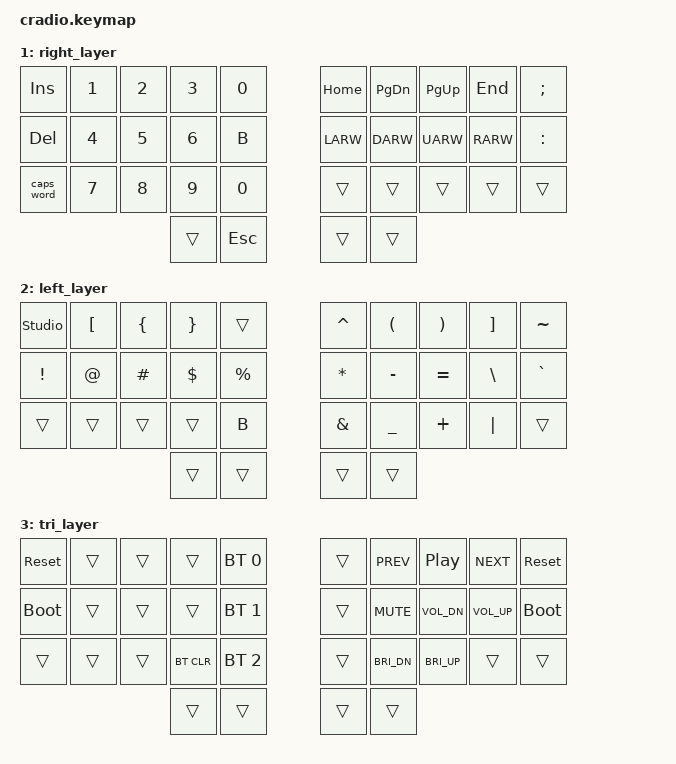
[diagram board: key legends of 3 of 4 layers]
// Copyright (c) 2022 The ZMK Contributors
// SPDX-License-Identifier: MIT

#include <behaviors.dtsi>
#include <dt-bindings/zmk/keys.h>
#include <dt-bindings/zmk/bt.h>

// Home row mods macro
#define HRML(k1,k2,k3,k4) &ht LCTRL k1  &ht LGUI k2  &ht LSHFT k3  &ht LALT k4
#define HRMR(k1,k2,k3,k4) &ht RALT k1  &ht RSHFT k2  &ht RGUI k3  &ht RCTRL k4

/ {
    behaviors {
        ht: hold_tap {
            compatible = "zmk,behavior-hold-tap";
            #binding-cells = <2>;
            flavor = "tap-preferred";
            tapping-term-ms = <220>;
            quick-tap-ms = <150>;
            require-prior-idle-ms = <100>;
            bindings = <&kp>, <&kp>;
        };
    };

    conditional_layers {
        compatible = "zmk,conditional-layers";
        tri_layer {
            if-layers = <1 2>;
            then-layer = <3>;
        };
    };

    keymap {
        compatible = "zmk,keymap";
        default_layer {
            bindings = <
        //╭──────────┬──────────┬──────────┬──────────┬──────────╮   ╭──────────┬──────────┬──────────┬──────────┬──────────╮
        //│  Q       │  W       │  E       │  R       │  T       │   │  Y       │  U       │  I       │  O       │  P       │
            &kp Q      &kp W      &kp E      &kp R      &kp T          &kp Y      &kp U      &kp I      &kp O      &kp P
        //├──────────┼──────────┼──────────┼──────────┼──────────┤   ├──────────┼──────────┼──────────┼──────────┼──────────┤
        //│  A       │  S       │  D       │  F       │  G       │   │  H       │  J       │  K       │  L       │ ' "      │
            HRML(A,        S,         D,         F)     &kp G          &kp H      HRMR(J,        K,         L,        SQT)
        //├──────────┼──────────┼──────────┼──────────┼──────────┤   ├──────────┼──────────┼──────────┼──────────┼──────────┤
        //│  Z       │  X       │  C       │  V       │  B       │   │  N       │  M       │ , <      │ . >      │ / ?      │
            &kp Z      &kp X      &kp C      &kp V      &kp B          &kp N      &kp M      &kp COMMA  &kp DOT    &kp FSLH
        //╰──────────┴──────────┴──────────┼──────────┼──────────┤   ├──────────┼──────────┼──────────┴──────────┴──────────╯
                                            &lt 2 TAB   &kp SPACE    &kp ENTER  &lt 1 BSPC
        //                                 ╰──────────┴──────────╯   ╰──────────┴──────────╯
            >;
        };

	// Кнопка B сломалась(((
        right_layer {
            bindings = <
        //╭──────────┬──────────┬──────────┬──────────┬──────────╮   ╭──────────┬──────────┬──────────┬──────────┬──────────╮
        //│ INSERT   │  1       │  2       │  3       │  0       │   │ HOME     │ PAGE DN  │ PAGE UP  │ END      │  ;       │
            &kp INS    &kp N1     &kp N2     &kp N3     &kp N0         &kp HOME   &kp PG_DN  &kp PG_UP  &kp END    &kp SEMI
        //├──────────┼──────────┼──────────┼──────────┼──────────┤   ├──────────┼──────────┼──────────┼──────────┼──────────┤
        //│ DELETE   │  4       │  5       │  6       │  B       │   │ LEFT     │ DOWN     │ UP       │ RIGHT    │  :       │
            &kp DEL    &kp N4     &kp N5     &kp N6     &kp B          &kp LARW   &kp DARW   &kp UARW   &kp RARW   &kp COLON
        //├──────────┼──────────┼──────────┼──────────┼──────────┤   ├──────────┼──────────┼──────────┼──────────┼──────────┤
        //│ CAPS     │  7       │  8       │  9       │  0       │   │          │          │          │          │          │
           &caps_word  &kp N7     &kp N8     &kp N9     &kp N0         &trans     &trans     &trans     &trans     &trans
        //╰──────────┴──────────┴──────────┼──────────┼──────────┤   ├──────────┼──────────┼──────────┴──────────┴──────────╯
                                             &trans     &kp ESC        &trans     &trans
        //                                 ╰──────────┴──────────╯   ╰──────────┴──────────╯
            >;
        };

        left_layer {
            bindings = <
        //╭──────────┬──────────┬──────────┬──────────┬──────────╮   ╭──────────┬──────────┬──────────┬──────────┬──────────╮
        //│          │  [       │  {       │  }       │          │   │  ^       │  (       │  )       │  ]       │  ~       │
          &studio_unlock  &kp LBKT  &kp LBRC  &kp RBRC   &trans        &kp CARET  &kp LPAR   &kp RPAR   &kp RBKT   &kp TILDE
        //├──────────┼──────────┼──────────┼──────────┼──────────┤   ├──────────┼──────────┼──────────┼──────────┼──────────┤
        //│  !       │  @       │  #       │  $       │  %       │   │  *       │  -       │  =       │  \       │  `       │
            &kp EXCL   &kp AT     &kp HASH   &kp DLLR   &kp PRCNT      &kp ASTRK  &kp MINUS  &kp EQUAL  &kp BSLH   &kp GRAVE
        //├──────────┼──────────┼──────────┼──────────┼──────────┤   ├──────────┼──────────┼──────────┼──────────┼──────────┤
        //│          │          │          │          │          │   │  &       │  _       │  +       │  │       │          │
            &trans     &trans     &trans     &trans     &kp B          &kp AMPS   &kp UNDER  &kp PLUS   &kp PIPE   &trans
        //╰──────────┴──────────┴──────────┼──────────┼──────────┤   ├──────────┼──────────┼──────────┴──────────┴──────────╯
                                             &trans     &trans         &trans     &trans
        //                                 ╰──────────┴──────────╯   ╰──────────┴──────────╯
            >;
        };

        tri_layer {
            bindings = <
        //╭──────────┬──────────┬──────────┬──────────┬──────────╮   ╭──────────┬──────────┬──────────┬──────────┬──────────╮
        //│ RESET    │          │          │          │PROFILE 0 │   │          │          │          │          │  RESET   │
           &sys_reset  &trans     &trans     &trans    &bt BT_SEL 0    &trans   &kp C_PREV  &kp C_PLAY_PAUSE  &kp C_NEXT    &sys_reset
        //├──────────┼──────────┼──────────┼──────────┼──────────┤   ├──────────┼──────────┼──────────┼──────────┼──────────┤
        //│BOOTLOADER│          │          │          │PROFILE 1 │   │          │          │          │          │BOOTLOADER│
          &bootloader  &trans     &trans     &trans    &bt BT_SEL 1    &trans  &kp K_MUTE  &kp K_VOL_DN  &kp K_VOL_UP  &bootloader
        //├──────────┼──────────┼──────────┼──────────┼──────────┤   ├──────────┼──────────┼──────────┼──────────┼──────────┤
        //│          │          │          │ CLEAR BT │PROFILE 2 │   │          │          │          │          │          │
            &trans     &trans     &trans    &bt BT_CLR &bt BT_SEL 2    &trans  &kp C_BRI_DN  &kp C_BRI_UP  &trans  &trans
        //╰──────────┴──────────┴──────────┼──────────┼──────────┤   ├──────────┼──────────┼──────────┴──────────┴──────────╯
                                             &trans     &trans         &trans     &trans
        //                                 ╰──────────┴──────────╯   ╰──────────┴──────────╯
            >;
        };
    };
};
